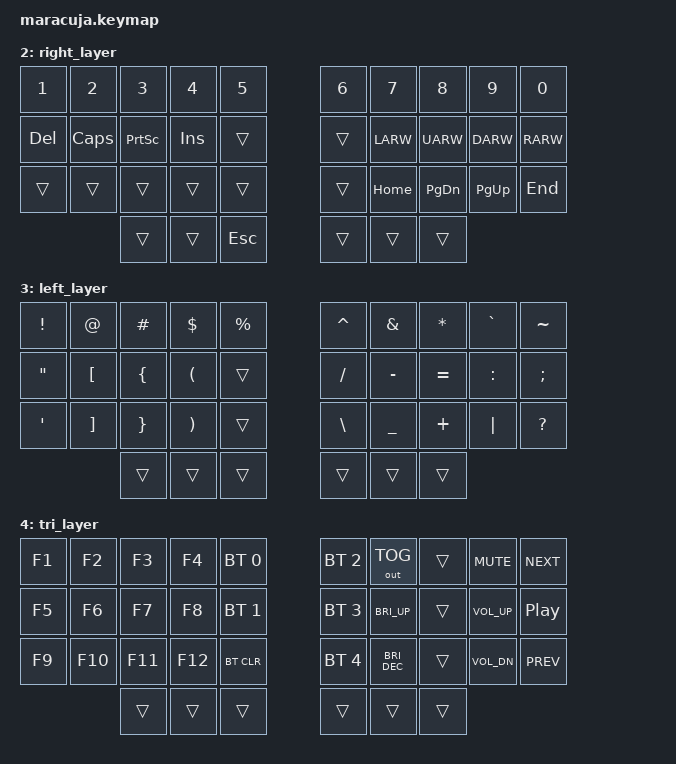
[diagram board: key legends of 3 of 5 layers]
/*
 * Copyright (c) 2020 The ZMK Contributors
 *
 * SPDX-License-Identifier: MIT
 */

#include <behaviors.dtsi>
#include <dt-bindings/zmk/keys.h>
#include <dt-bindings/zmk/bt.h>
#include <dt-bindings/zmk/outputs.h>
#include <dt-bindings/zmk/ext_power.h>
#include <dt-bindings/zmk/mouse.h>

#include "../zmk-nodefree-config/helper.h"
#include "../zmk-nodefree-config/international_chars/german.dtsi"

#define MAC 0
#define WIN 1
#define RIG 2
#define LEF 3
#define TRI 4

#define AUML APOS
#define OUML SEMI
#define UUML LBKT
#define DE_SS MINUS
#define DE_MINS SLASH
#define DE_DLLR LS(N4)
#define DE_PCNT LS(N5)
#define DE_AMPSD LS(N6)
#define DE_FSLH LS(N7)
#define DE_PLUS LS(RBRC)
#define DE_STAR RBRC
#define DE_EQUL LS(N0)
#define DE_AT RA(Q)
#define DE_HASH BSLH
#define DE_LT GRAVE
#define DE_GT LS(GRAVE)
#define DE_PIPE RA(GRAVE)
#define DE_BSLH RA(MINUS)
#define DE_EXCL LS(N1)

// Home row mods macro
#define HRML(k2,k3,k4) &ht LCTRL k2  &ht LALT k3  &ht LGUI k4
#define HRMR(k1,k2,k3) &ht RGUI k1  &ht RALT k2 &ht RCTRL k3
#define LHRML(k2,k3,k4) &ht LCTRL k2  &ht LALT k3  &ht LGUI k4
#define LHRMR(k1,k2,k3) &ht RGUI k1  &ht RALT k2  &ht RCTRL k3

//&lt {
//    tapping-term-ms = <250>;
//    quick_tap_ms = <150>;
//    flavor = "tap-preferred";
//};

&caps_word {
    continue-list = <UNDERSCORE DE_MINS BSPC DELETE>;
};

&mt {
  quick-tap-ms = <200>;
};

// Macro to apply momentary-layer-on-hold/toggle-layer-on-tap to a specific layer
#define MO_TOG(layer) &mo_tog layer layer   

/ {
     macros {
        auml: auml {
            compatible = "zmk,behavior-macro";
            #binding-cells = <0>;
            bindings
                = <&macro_tap &kp LA(U) >
                , <&macro_tap &kp A>
                ;
        };
        ouml: ouml {
            compatible = "zmk,behavior-macro";
            #binding-cells = <0>;
            bindings
                = <&macro_tap &kp LA(U) >
                , <&macro_tap &kp O>
                ;
        };
        uuml: uuml {
            compatible = "zmk,behavior-macro";
            #binding-cells = <0>;
            bindings
                = <&macro_tap &kp LA(U) >
                , <&macro_tap &kp U>
                ;
        };
        eszett: eszett {
            compatible = "zmk,behavior-macro";
            #binding-cells = <0>;
            bindings
                = <&macro_press &kp LA(S) >
                ;
        };
    };
  behaviors {
     ht: hold_tap {
            label = "hold_tap";
            compatible = "zmk,behavior-hold-tap";
            #binding-cells = <2>;
            flavor = "tap-preferred";
            tapping-term-ms = <220>;
            quick-tap-ms = <150>;
            global-quick-tap;
            bindings = <&kp>, <&kp>;
     };
    hm: homerow_mods {
        compatible = "zmk,behavior-hold-tap";
        label = "HOMEROW_MODS";
        require-prior-idle-ms = <250>;
        #binding-cells = <2>;
        bindings = <&kp>, <&kp>;
        tapping-term-ms = <200>;
        flavor = "tap-preferred";
    };
    hsl: homerow_shift_l {
        compatible = "zmk,behavior-hold-tap";
        label = "HOMEROW_SHIFT_L";
        #binding-cells = <2>;
        bindings = <&kp>, <&kp>;
        tapping-term-ms = <160>;
        flavor = "balanced";
        hold-trigger-key-positions = <5 6 7 8 9 15 16 17 18 19 25 26 27 28 29 33 34 35>;
    };
    hsr: homerow_shift_r {
        compatible = "zmk,behavior-hold-tap";
        label = "HOMEROW_SHIFT_R";
        #binding-cells = <2>;
        bindings = <&kp>, <&kp>;
        tapping-term-ms = <160>;
        flavor = "balanced";
        hold-trigger-key-positions = <0 1 2 3 4 10 11 12 13 14 20 21 22 23 24 30 31 32>;
    };
    mo_tog: behavior_mo_tog {
        compatible = "zmk,behavior-hold-tap";
        label = "mo_tog";
        #binding-cells = <2>;
        flavor = "hold-preferred";
        tapping-term-ms = <200>;
        bindings = <&mo>, <&tog>;
    };
    de_quot: german_quote_doublequote {
        compatible = "zmk,behavior-mod-morph";
        label = "DE_QUOTES";
        #binding-cells = <0>;
        bindings = <&kp LS(BSLH)>, <&kp LS(N2)>;
        mods = <(MOD_LSFT|MOD_RSFT)>;
    };
  };

  conditional_layers {
      compatible = "zmk,conditional-layers";
      tri_layer {
          if-layers = <RIG LEF>;
          then-layer = <TRI>;
      };
  };

  combos {
    compatible = "zmk,combos";

    #define COMBO(NAME, BINDINGS, KEYPOS, PREIDLE) \
      combo_##NAME { \
        bindings = <BINDINGS>; \
        key-positions = <KEYPOS>; \
        require-prior-idle-ms = <PREIDLE>; \
      };

    /*
      ╭─────────────────────╮  ╭─────────────────────╮
      │   0   1   2   3   4 │  │  5   6   7   8  9   │
      │  10  11  12  13  14 │  │ 15  16  17  18  19  │
      │  20  21  22  23  24 │  | 25  26  27  28  29  │
      ╰────────╮ 30  31  32 │  │ 33  34  35 ╭────────╯
               ╰────────────╯  ╰────────────╯
    */

    COMBO(auml, &auml, 8 9, 0)
    COMBO(ouml, &ouml, 18 19, 0)
    COMBO(uuml, &uuml, 28 29, 0)
    COMBO(szuml, &eszett, 7 8, 0)
  };

keymap {
        compatible = "zmk,keymap";
        default_layer {
            bindings = <
        //╭──────────┬──────────┬──────────┬──────────┬──────────╮   ╭──────────┬──────────┬──────────┬──────────┬──────────╮
        //│  Q       │  W       │  F       │  R       │  T       │   │  Y       │  U       │  I       │  O       │  P       │
            &kp Q      &kp W      &kp F      &kp R      &kp T          &kp Y      &kp U      &kp I      &kp O      &kp P
        //├──────────┼──────────┼──────────┼──────────┼──────────┤   ├──────────┼──────────┼──────────┼──────────┼──────────┤
        //│  A       │ S |alt   │ D |ctrl  │  E |cmd  │  G       │   │  H       │  J |cmd  │  K |ctrl │  L |alt  │BACKSPACE │
            &kp A     HRML(S,         D,         E)     &kp G          &kp H      HRMR(J,        K,           L)   &kp BSPC
        //├──────────┼──────────┼──────────┼──────────┼──────────┤   ├──────────┼──────────┼──────────┼──────────┼──────────┤
        //│  Z       │  X       │  C       │  V       │  B       │   │  N       │  M       │ , <      │ . >      │ ENTER    │
            &kp Z      &kp X      &kp C      &kp V      &kp B          &kp N      &kp M      &kp COMMA  &kp DOT    &kp ENTER
        //╰──────────┴──────────┴──────────┼──────────┼──────────┤   ├──────────┼──────────┼──────────┴──────────┴──────────╯
                                &lt LEF TAB &kp LSHIFT &kp LSHIFT     &kp SPACE  &kp SPACE  &lt RIG TAB
        //                      ╰──────────┴──────────┴──────────╯   ╰──────────┴──────────┴──────────╯
            >;
        };

        // TODO: This layer can be removed since the home row mods are now equal 
        // and will be managed by keysharp (if early access is sufficient) or simliar 
        // to imitate macOS keybind behaviour:
        // https://www.autohotkey.com/boards/viewtopic.php?f=81&t=125220
        linux_layer {
            bindings = <
        //╭──────────┬──────────┬──────────┬──────────┬──────────╮   ╭──────────┬──────────┬──────────┬──────────┬──────────╮
        //│  Q       │  W       │  E       │  R       │  T       │   │  Y       │  U       │  I       │  O       │  P       │
            &kp Q      &kp W      &kp E      &kp R      &kp T          &kp Y      &kp U      &kp I      &kp O      &kp P
        //├──────────┼──────────┼──────────┼──────────┼──────────┤   ├──────────┼──────────┼──────────┼──────────┼──────────┤
        //│  A       │  S       │  D       │  F       │  G       │   │  H       │  J       │  K       │  L       │BACKSPACE │
            &kp A    LHRML(S,         D,         F)     &kp G          &kp H      LHRMR(J,        K,         L)   &kp BSPC
        //├──────────┼──────────┼──────────┼──────────┼──────────┤   ├──────────┼──────────┼──────────┼──────────┼──────────┤
        //│  Z       │  X       │  C       │  V       │  B       │   │  N       │  M       │ , <      │ . >      │ ENTER    │
            &kp Z      &kp X      &kp C      &kp V      &kp B          &kp N      &kp M      &kp COMMA  &kp DOT    &kp ENTER
        //╰──────────┴──────────┴──────────┼──────────┼──────────┤   ├──────────┼──────────┼──────────┴──────────┴──────────╯
                                &lt LEF TAB &kp LSHIFT &kp LSHIFT     &kp SPACE  &kp SPACE  &lt RIG TAB
        //                      ╰──────────┴──────────┴──────────╯   ╰──────────┴──────────┴──────────╯
            >;
        };

        right_layer {
            bindings = <
        //╭──────────┬──────────┬──────────┬──────────┬──────────╮   ╭──────────┬──────────┬──────────┬──────────┬──────────╮
        //│ 1        │  2       │  3       │  4       │  5       │   │ 6        │ 7        │ 8        │ 9        │   0      │
            &kp N1    &kp N2     &kp N3     &kp N4     &kp N5          &kp N6     &kp N7     &kp N8     &kp N9      &kp N0
        //├──────────┼──────────┼──────────┼──────────┼──────────┤   ├──────────┼──────────┼──────────┼──────────┼──────────┤
        //│ DELETE   │ CapsLock │ PrintSc  │  INSERT  │          |   |          │ LEFT     │ UP       │ DOWN     │ RIGHT    │
            &kp DEL   &kp CAPS   &kp PSCRN  &kp INS     &trans         &trans     &kp LARW   &kp UARW   &kp DARW   &kp RARW 
        //├──────────┼──────────┼──────────┼──────────┼──────────┤   ├──────────┼──────────┼──────────┼──────────┼──────────┤
        //│          │          │          │          │          │   │          │ HOME     │ PAGE DN  │ PAGE UP  │ END      │
            &trans    &trans     &trans     &trans      &trans         &trans     &kp HOME   &kp PG_DN  &kp PG_UP  &kp END 
        //╰──────────┴──────────┴──────────┼──────────┼──────────┤   ├──────────┼──────────┼──────────┴──────────┴──────────╯
                                  &trans    &trans     &kp ESC        &trans     &trans     &trans
        //                      ╰──────────┴──────────┴──────────╯   ╰──────────┴──────────┴──────────╯
            >;
        };

        left_layer {
            bindings = <
        //╭──────────┬──────────┬──────────┬──────────┬──────────╮   ╭──────────┬──────────┬──────────┬──────────┬──────────╮
        //│  !       │  @       │  #       │  $       │  %       │   │  ^       │  &       │  *       │  `       │  ~       │
            &kp EXCL   &kp AT     &kp HASH   &kp DLLR   &kp PRCNT      &kp CARET  &kp AMPS   &kp ASTRK  &kp GRAVE   &kp TILDE
        //├──────────┼──────────┼──────────┼──────────┼──────────┤   ├──────────┼──────────┼──────────┼──────────┼──────────┤
        //│  "       │  [       │  {       │  (       │          │   │   /      │  -       │  =       │     :    │  ;       │
            &kp DQT  &kp LBKT   &kp LBRC   &kp LPAR   &trans          &kp FSLH   &kp MINUS  &kp EQUAL  &kp COLON   &kp SEMI
        //├──────────┼──────────┼──────────┼──────────┼──────────┤   ├──────────┼──────────┼──────────┼──────────┼──────────┤
        //│  '       │  ]       │  }       │  )       │          │   │    \     │  _       │  +       │  │       │   ?      │
            &kp SQT     &kp RBKT   &kp RBRC   &kp RPAR   &trans         &kp BSLH   &kp UNDER  &kp PLUS   &kp PIPE  &kp QMARK
        //╰──────────┴──────────┴──────────┼──────────┼──────────┤   ├──────────┼──────────┼──────────┴──────────┴──────────╯
                                  &trans     &trans     &trans         &trans     &trans     &trans
        //                      ╰──────────┴──────────┴──────────╯   ╰──────────┴──────────┴──────────╯
            >;
        };

        tri_layer {
            bindings = <
        //╭──────────┬──────────┬──────────┬───────────┬────────────╮   ╭────────────┬────────────┬──────────┬───────────┬──────────╮
        //│  F1      │  F2      │  F3      │  F4       │ PROFILE 0  │   │ PROFILE 2  │ TOGGLEOUT  │          │ VOL MUTE  │ NEXTSONG │
            &kp F1     &kp F2     &kp F3     &kp F4     &bt BT_SEL 0     &bt BT_SEL 2  &out OUT_TOG  &trans   &kp C_MUTE  &kp C_NEXT
        //├──────────┼──────────┼──────────┼───────────┼────────────┤   ├────────────┼────────────┼──────────┼───────────┼──────────┤
        //│  F5      │  F6      │  F7      │  F8       │ PROFILE 1  │   │ PROFILE 3  │ INC BRIGHT │          │  VOL UP   │PAUSEMUSIC│
            &kp F5     &kp F6     &kp F7     &kp F8     &bt BT_SEL 1     &bt BT_SEL 3  &kp C_BRI_UP  &trans   &kp C_VOL_UP  &kp C_PP
        //├──────────┼──────────┼──────────┼───────────┼────────────┤   ├────────────┼────────────┼──────────┼───────────┼──────────┤
        //│  F9      │  F10     │  F11     │  F12      │  CLEAR BT  │   │ PROFILE 4  │ DEC BRIGHT │          |  VOL DOWN │ PREVSONG │
            &kp F9     &kp F10    &kp F11    &kp F12     &bt BT_CLR      &bt BT_SEL 4  &kp C_BRI_DEC  &trans  &kp C_VOL_DN &kp C_PREV
        //╰──────────┴──────────┴──────────┼───────────┼────────────┤   ├────────────┼────────────┼──────────┴───────────┴──────────╯
                                 &trans      &trans     &trans            &trans       &trans       &trans
        //                      ╰──────────┴───────────┴────────────╯   ╰────────────┴────────────┴──────────╯
            >;
        };
    };
};

